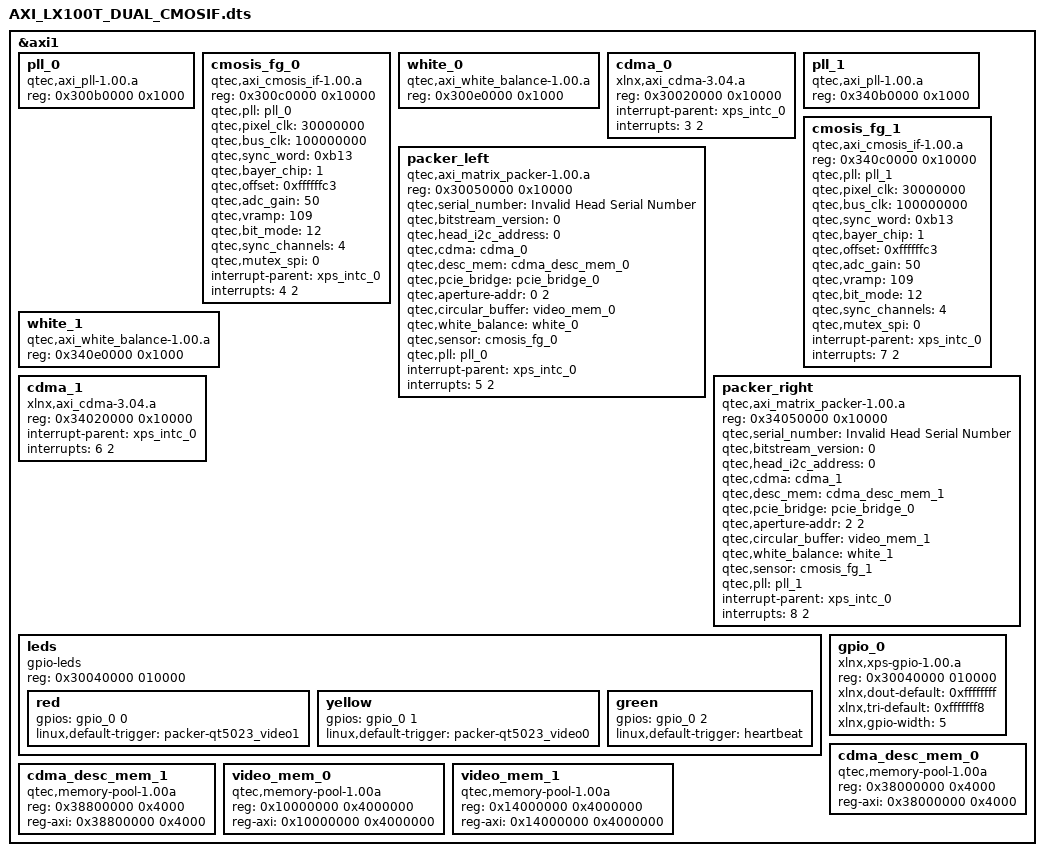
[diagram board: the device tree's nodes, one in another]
/dts-v1/;

/include/ "qt5023.dtsi"

&axi1 {
	pll_0: pll_0 {
		#address-cells = <1>;
		#size-cells = <1>;
	    	compatible = "qtec,axi_pll-1.00.a";
		reg = < 0x300b0000 0x1000 >;
	};
	cmosis_fg_0: cmosis_fg_0 {
		#address-cells = <1>;
		#size-cells = <1>;
	       	compatible = "qtec,axi_cmosis_if-1.00.a";
		reg = < 0x300c0000 0x10000 >;
		qtec,pll = < &pll_0 >;
		qtec,pixel_clk = < 30000000 >;
		qtec,bus_clk =   < 100000000 >;
		qtec,sync_word = < 0xb13 >;
		qtec,bayer_chip = <1> ;
		qtec,offset = <0xffffffc3> ; /* -61*/
		qtec,adc_gain = <50> ;
		qtec,vramp = <109> ;
		qtec,bit_mode = < 12 >;
		qtec,sync_channels = < 4 >;
		qtec,mutex_spi = < 0 >; /* Mutex group 0*/
		interrupt-parent = <&xps_intc_0>;
		interrupts = < 4 2 >;
	};
	white_0: white_0 {
		#address-cells = <1>;
		#size-cells = <1>;
	    	compatible = "qtec,axi_white_balance-1.00.a";
		reg = < 0x300e0000 0x1000 >;
	};
	cdma_0: cdma_0{
		#address-cells = <1>;
		#size-cells = <1>;
	     	compatible = "xlnx,axi_cdma-3.04.a";
		reg = < 0x30020000 0x10000 >;
		interrupt-parent = <&xps_intc_0>;
		interrupts = < 3 2 >;
	};
	packer_left: packer_left{
		#address-cells = <1>;
		#size-cells = <1>;
	     	compatible = "qtec,axi_matrix_packer-1.00.a";
		reg = < 0x30050000 0x10000 >;
		qtec,serial_number = "Invalid Head Serial Number";
		qtec,bitstream_version = < 0 >;
		qtec,head_i2c_address = < 0 >;
		qtec,cdma = <&cdma_0>;
		qtec,desc_mem= <&cdma_desc_mem_0>;
		qtec,pcie_bridge= <&pcie_bridge_0>;
		qtec,aperture-addr= < 0  2 >;
		qtec,circular_buffer= <&video_mem_0>;
		qtec,white_balance= <&white_0>;
		qtec,sensor = <&cmosis_fg_0>;
		qtec,pll = < &pll_0 >;
		interrupt-parent = <&xps_intc_0>;
		interrupts = < 5 2 >;
	};
	pll_1: pll_1 {
		#address-cells = <1>;
		#size-cells = <1>;
	    	compatible = "qtec,axi_pll-1.00.a";
		reg = < 0x340b0000 0x1000 >;
	};
	cmosis_fg_1: cmosis_fg_1 {
		#address-cells = <1>;
		#size-cells = <1>;
	       	compatible = "qtec,axi_cmosis_if-1.00.a";
		reg = < 0x340c0000 0x10000 >;
		qtec,pll = < &pll_1 >;
		qtec,pixel_clk = < 30000000 >;
		qtec,bus_clk =   < 100000000 >;
		qtec,sync_word = < 0xb13 >;
		qtec,bayer_chip = <1> ;
		qtec,offset = <0xffffffc3> ; /* -61*/
		qtec,adc_gain = <50> ;
		qtec,vramp = <109> ;
		qtec,bit_mode = < 12 >;
		qtec,sync_channels = < 4 >;
		qtec,mutex_spi = < 0 >; /* Mutex group 0*/
		interrupt-parent = <&xps_intc_0>;
		interrupts = < 7 2 >;
	};
	white_1: white_1 {
		#address-cells = <1>;
		#size-cells = <1>;
	    	compatible = "qtec,axi_white_balance-1.00.a";
		reg = < 0x340e0000 0x1000 >;
	};
	cdma_1: cdma_1{
		#address-cells = <1>;
		#size-cells = <1>;
	     	compatible = "xlnx,axi_cdma-3.04.a";
		reg = < 0x34020000 0x10000 >;
		interrupt-parent = <&xps_intc_0>;
		interrupts = < 6 2 >;
	};
	packer_right: packer_right{
		#address-cells = <1>;
		#size-cells = <1>;
	     	compatible = "qtec,axi_matrix_packer-1.00.a";
		reg = < 0x34050000 0x10000 >;
		qtec,serial_number = "Invalid Head Serial Number";
		qtec,bitstream_version = < 0 >;
		qtec,head_i2c_address = < 0 >;
		qtec,cdma = <&cdma_1>;
		qtec,desc_mem= <&cdma_desc_mem_1>;
		qtec,pcie_bridge= <&pcie_bridge_0>;
		qtec,aperture-addr= < 2  2 >;
		qtec,circular_buffer= <&video_mem_1>;
		qtec,white_balance= <&white_1>;
		qtec,sensor = <&cmosis_fg_1>;
		qtec,pll = < &pll_1 >;
		interrupt-parent = <&xps_intc_0>;
		interrupts = < 8 2 >;
	};

	/*Leds*/
	leds {
	compatible = "gpio-leds";
		reg = < 0x30040000 010000 >;
		red {
			gpios = <&gpio_0 0 0>;
			linux,default-trigger = "packer-qt5023_video1";
		};
		yellow {
			gpios = <&gpio_0 1 0>;
			linux,default-trigger = "packer-qt5023_video0";
		};
		green {
			gpios = <&gpio_0 2 0>;
			linux,default-trigger = "heartbeat";
		};
	};

	gpio_0: gpio_0 {
		#gpio-cells = <2>;
		compatible = "xlnx,xps-gpio-1.00.a";
		reg = < 0x30040000 010000 >;
		xlnx,dout-default = < 0xffffffff >;
		xlnx,tri-default =  < 0xfffffff8 >;
		xlnx,gpio-width = < 5 >;
	};

	/*Memory resources*/
	cdma_desc_mem_0: cdma_desc_mem_0 {
		#address-cells = <1>;
		#size-cells = <1>;
	     	compatible = "qtec,memory-pool-1.00a";
		reg = < 0x38000000 0x4000 >;
		reg-axi = < 0x38000000 0x4000 >;
	};
	cdma_desc_mem_1: cdma_desc_mem_1 {
		#address-cells = <1>;
		#size-cells = <1>;
	     	compatible = "qtec,memory-pool-1.00a";
		reg = < 0x38800000 0x4000 >;
		reg-axi = < 0x38800000 0x4000 >;
	};
	video_mem_0: video_mem_0 {
		#address-cells = <1>;
		#size-cells = <1>;
	     	compatible = "qtec,memory-pool-1.00a";
		reg = < 0x10000000 0x4000000 >;
		reg-axi = < 0x10000000 0x4000000>; //Duplicated
	};
	video_mem_1: video_mem_1 {
		#address-cells = <1>;
		#size-cells = <1>;
	     	compatible = "qtec,memory-pool-1.00a";
		reg = < 0x14000000 0x4000000 >;
		reg-axi = < 0x14000000 0x4000000>; //Duplicated
	};
};
